# AT90PWM161 device description
Architecture: AVR8; Family: megaAVR
Registers are 8-bit, access not given, no defined reset value unless marked. A register's access mark holds for its fields unless they carry their own. Offsets are from the block's base; [hi:lo] are bit positions.

## FUSE — Fuses
Instances: FUSE 0 in fuses
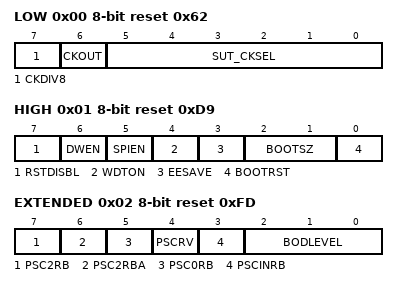
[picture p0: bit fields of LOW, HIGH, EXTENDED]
0x00 LOW reset 0x62
  [7] CKDIV8 — Divide clock by 8 internally
  [6] CKOUT — Clock output on PORTD1
  [5:0] SUT_CKSEL — Select Clock Source
    0=EXTCLK_PLLIN_RC_8MHZ_6CK_14CK_0MS (Ext. CK; PLLin: RC8; SUT: 6CK/14CK+0ms; [CKSEL=0000 SUT=00]); 16=EXTCLK_PLLIN_RC_8MHZ_6CK_14CK_4MS1 (Ext. CK; PLLin: RC8 MHz; SUT:6 CK/14CK+4.1 ms; [CKSEL=0000 SUT=01]); 32=EXTCLK_PLLIN_RC_8MHZ_6CK_14CK_65MS (Ext. CK; PLLin: RC8 MHz; SUT:6 CK/14CK+65 ms; [CKSEL=0000 SUT=10]); 2=RC_8MHZ_PLLIN_RC_8MHZ_6CK_14CK_0MS (RC8 MHz; PLLin: RC8; SUT: 6CK/14CK+0ms; [CKSEL=0010 SUT=00]); 18=RC_8MHZ_PLLIN_RC_8MHZ_6CK_14CK_4MS1 (RC8 MHz; PLLin: RC8; SUT: 6CK/14CK+4.1 ms; [CKSEL=0010 SUT=01]); 34=RC_8MHZ_PLLIN_RC_8MHZ_6CK_14CK_65MS (RC8 MHz; PLLin: RC8; SUT: 6CK/14CK+65 ms; [CKSEL=0010 SUT=10]); 8=XOSC_PLLIN_RC_8MHZ_258CK_14CK_4MS1 (XOSC.9-3MHz; PLLin: RC8; SUT: 258CK/14CK+4.1 ms; [CKSEL=1000 SUT=00]); 24=XOSC_PLLIN_RC_8MHZ_258CK_14CK_65MS (XOSC.9-3MHz; PLLin: RC8; SUT: 258CK/14CK+65 ms; [CKSEL=1000 SUT=01]); 40=XOSC_PLLIN_RC_8MHZ_1KCK_14CK_0MS (XOSC.9-3MHz; PLLin: RC8; SUT: 1KCK/14CK+0 ms; [CKSEL=1000 SUT=10]); 56=XOSC_PLLIN_RC_8MHZ_1KCK_14CK_4MS1 (XOSC.9-3MHz; PLLin: RC8; SUT: 1KCK/14CK+4.1 ms; [CKSEL=1000 SUT=11]); 9=XOSC_PLLIN_RC_8MHZ_1KCK_14CK_65MS (XOSC.9-3MHz; PLLin: RC8; SUT: 1KCK/14CK+65 ms; [CKSEL=1001 SUT=00]); 25=XOSC_PLLIN_RC_8MHZ_16KCK_14CK_0MS (XOSC.9-3MHz; PLLin: RC8; SUT: 16KCK/14CK+0 ms; [CKSEL=1001 SUT=01]); 41=XOSC_PLLIN_RC_8MHZ_16KCK_14CK_4MS1 (XOSC.9-3MHz; PLLin: RC8; SUT: 16KCK/14CK+4.1 ms; [CKSEL=1001 SUT=10]); 57=XOSC_PLLIN_RC_8MHZ_16KCK_14CK_65MS (XOSC.9-3MHz; PLLin: RC8; SUT: 16KCK/14CK+65 ms; [CKSEL=1001 SUT=11]); 10=XOSC_3MHZ_8MHZ_PLLIN_RC_8MHZ_258CK_14CK_4MS1 (XOSC3-8MHz; PLLin: RC8; SUT: 258CK/14CK+4.1 ms; [CKSEL=1010 SUT=00]); 26=XOSC_3MHZ_8MHZ_PLLIN_RC_8MHZ_258CK_14CK_65MS (XOSC3-8MHz; PLLin: RC8; SUT: 258CK/14CK+65 ms; [CKSEL=1010 SUT=01]); 42=XOSC_3MHZ_8MHZ_PLLIN_RC_8MHZ_1KCK_14CK_0MS (XOSC3-8MHz; PLLin: RC8; SUT: 1KCK/14CK+0 ms; [CKSEL=1010 SUT=10]); 58=XOSC_3MHZ_8MHZ_PLLIN_RC_8MHZ_1KCK_14CK_4MS1 (XOSC3-8MHz; PLLin: RC8; SUT: 1KCK/14CK+4.1 ms; [CKSEL=1010 SUT=11]); 11=XOSC_3MHZ_8MHZ_PLLIN_RC_8MHZ_1KCK_14CK_65MS (XOSC3-8MHz; PLLin: RC8; SUT: 1KCK/14CK+65 ms; [CKSEL=1011 SUT=00]); 27=XOSC_3MHZ_8MHZ_PLLIN_RC_8MHZ_16KCK_14CK_0MS (XOSC3-8MHz; PLLin: RC8; SUT: 16KCK/14CK+0 ms; [CKSEL=1011 SUT=01]); 43=XOSC_3MHZ_8MHZ_PLLIN_RC_8MHZ_16KCK_14CK_4MS1 (XOSC3-8MHz; PLLin: RC8; SUT: 16KCK/14CK+4.1 ms; [CKSEL=1011 SUT=10]); 59=XOSC_3MHZ_8MHZ_PLLIN_RC_8MHZ_16KCK_14CK_65MS (XOSC3-8MHz; PLLin: RC8; SUT: 16KCK/14CK+65 ms; [CKSEL=1011 SUT=11]); 12=XOSC_3MHZ_8MHZ_PLLIN_XOSC_258CK_14CK_4MS1 (XOSC3-8MHz; PLLin: XOSC; SUT: 258CK/14CK+4.1 ms; [CKSEL=1100 SUT=00]); 28=XOSC_3MHZ_8MHZ_PLLIN_XOSC_258CK_14CK_65MS (XOSC3-8MHz; PLLin: XOSC; SUT: 258CK/14CK+65 ms; [CKSEL=1100 SUT=01]); 44=XOSC_3MHZ_8MHZ_PLLIN_XOSC_1KCK_14CK_0MS (XOSC3-8MHz; PLLin: XOSC; SUT: 1KCK/14CK+0 ms; [CKSEL=1100 SUT=10]); 60=XOSC_3MHZ_8MHZ_PLLIN_XOSC_1KCK_14CK_4MS1 (XOSC3-8MHz; PLLin: XOSC; SUT: 1KCK/14CK+4.1 ms; [CKSEL=1100 SUT=11]); 13=XOSC_3MHZ_8MHZ_PLLIN_XOSC_1KCK_14CK_65MS (XOSC3-8MHz; PLLin: XOSC; SUT: 1KCK/14CK+65 ms; [CKSEL=1101 SUT=00); 29=XOSC_3MHZ_8MHZ_PLLIN_XOSC_16KCK_14CK_0MS (XOSC3-8MHz; PLLin: XOSC; SUT: 16KCK/14CK+0 ms; [CKSEL=1101 SUT=01]); 45=XOSC_3MHZ_8MHZ_PLLIN_XOSC_16KCK_14CK_4MS1 (XOSC3-8MHz; PLLin: XOSC; SUT: 16KCK/14CK+4.1 ms; [CKSEL=1101 SUT=10]); 61=XOSC_3MHZ_8MHZ_PLLIN_XOSC_16KCK_14CK_65MS (XOSC3-8MHz; PLLin: XOSC; SUT: 16KCK/14CK+65 ms; [CKSEL=1101 SUT=11]); 14=XOSC_8MHZ_16MHZ_PLLIN_RC_8MHZ_258CK_14CK_4MS1 (XOSC8-16MHz; PLLin: RC8; SUT: 258CK/14CK+4.1 ms; [CKSEL=1110 SUT=00]); 30=XOSC_8MHZ_16MHZ_PLLIN_RC_8MHZ_258CK_14CK_65MS (XOSC8-16MHz; PLLin: RC8; SUT: 258CK/14CK+65 ms; [CKSEL=1110 SUT=01]); 46=XOSC_8MHZ_16MHZ_PLLIN_RC_8MHZ_1KCK_14CK_0MS (XOSC8-16MHz; PLLin: RC8; SUT: 1KCK/14CK+0 ms; [CKSEL=1110 SUT=10]); 62=XOSC_8MHZ_16MHZ_PLLIN_RC_8MHZ_1KCK_14CK_4MS1 (XOSC8-16MHz; PLLin: RC8; SUT: 1KCK/14CK+4.1 ms; [CKSEL=1110 SUT=11]); 15=XOSC_8MHZ_16MHZ_PLLIN_RC_8MHZ_1KCK_14CK_65MS (XOSC8-16MHz; PLLin: RC8; SUT: 1KCK/14CK+65 ms; [CKSEL=1111 SUT=00]); 31=XOSC_8MHZ_16MHZ_PLLIN_RC_8MHZ_16KCK_14CK_0MS (XOSC8-16MHz; PLLin: RC8; SUT: 16KCK/14CK+0 ms; [CKSEL=1111 SUT=01]); 47=XOSC_8MHZ_16MHZ_PLLIN_RC_8MHZ_16KCK_14CK_4MS1 (XOSC8-16MHz; PLLin: RC8; SUT: 16KCK/14CK+4.1 ms; [CKSEL=1111 SUT=10]); 63=XOSC_8MHZ_16MHZ_PLLIN_RC_8MHZ_16KCK_14CK_65MS (XOSC8-16MHz; PLLin: RC8; SUT: 16KCK/14CK+65 ms; [CKSEL=1111 SUT=11]); 3=WDOSC_128KHZ_1KCK_14CK_0MS (WD128 KHz; SUT: 1KCK/14CK+0 ms; [CKSEL=0011 SUT=00]); 19=WDOSC_128KHZ_1KCK_14CK_4MS1 (WD128 KHz; SUT: 1KCK/14CK+4.1 ms; [CKSEL=0011 SUT=01]); 35=WDOSC_128KHZ_1KCK_14CK_65MS (WD128 KHz; SUT: 1KCK/14CK+65 ms; [CKSEL=0011 SUT=10]); 51=WDOSC_128KHZ_16KCK_14CK_0MS (WD128 KHz; SUT: 16KCK/14CK+0 ms; [CKSEL=0011 SUT=11]); 1=PLLCLK_DIV4_PLLIN_RC_8MHZ_1KCK_14CK_0MS (PLL/4; PLLin: RC8; SUT: 1KCK/14CK+0 ms; [CKSEL=0001 SUT=00]); 17=PLLCLK_DIV4_PLLIN_RC_8MHZ_1KCK_14CK_4MS (PLL/4; PLLin: RC8; SUT: 1KCK/14CK+4 ms; [CKSEL=0001 SUT=01]); 33=PLLCLK_DIV4_PLLIN_RC_8MHZ_1KCK_14CK_64MS (PLL/4; PLLin: RC8; SUT: 1KCK/14CK+64 ms; [CKSEL=0001 SUT=10]); 5=PLLCLK_DIV4_PLLIN_EXTCLK_16KCK_14CK_0MS (PLL/4; PLLin: Ext. CK; SUT: 16KCK/14CK+0 ms; [CKSEL=0101 SUT=00]); 21=PLLCLK_DIV4_PLLIN_EXTCLK_16KCK_14CK_4MS (PLL/4; PLLin: Ext. CK; SUT: 16KCK/14CK+4 ms; [CKSEL=0101 SUT=01]); 37=PLLCLK_DIV4_PLLIN_EXTCLK_16KCK_14CK_4MS (PLL/4; PLLin: Ext. CK; SUT: 16KCK/14CK+4 ms; [CKSEL=0101 SUT=10]); 53=PLLCLK_DIV4_PLLIN_EXTCLK_16KCK_14CK_64MS (PLL/4; PLLin: Ext. CK; SUT: 16KCK/14CK+64 ms; [CKSEL=0101 SUT=11]); 4=PLLCLK_DIV4_PLLIN_XOSC_1KCK_14CK_0MS (PLL/4; PLLin: XOSC; SUT: 1KCK/14CK+0 ms; [CKSEL=0100 SUT=00]); 20=PLLCLK_DIV4_PLLIN_XOSC_1KCK_14CK_4MS (PLL/4; PLLin: XOSC; SUT: 1KCK/14CK+4 ms; [CKSEL=0100 SUT=01]); 36=PLLCLK_DIV4_PLLIN_XOSC_1KCK_14CK_64MS (PLL/4; PLLin: XOSC; SUT: 1KCK/14CK+64 ms; [CKSEL=0100 SUT=10]); 52=PLLCLK_DIV4_PLLIN_XOSC_16KCK_14CK_0MS (PLL/4; PLLin: XOSC; SUT: 16KCK/14CK+0 ms; [CKSEL=0100 SUT=11]); 6=RC_1MHZ_1KCK_14CK_0MS (RC 1 MHz; SUT: 1KCK/14CK+0 ms; [CKSEL=0110 SUT=00]); 22=RC_1MHZ_1KCK_14CK_4MS1 (RC 1 MHz; SUT: 1KCK/14CK+4.1 ms; [CKSEL=0110 SUT=01]); 38=RC_1MHZ_1KCK_14CK_65MS (RC 1 MHz; SUT: 1KCK/14CK+65 ms; [CKSEL=0110 SUT=10])
0x01 HIGH reset 0xD9
  [7] RSTDISBL — Reset Disabled (Enable PE0 as I/O pin)
  [6] DWEN — Debug Wire enable
  [5] SPIEN — Serial program downloading (SPI) enabled
  [4] WDTON — Watch-dog Timer always on
  [3] EESAVE — Preserve EEPROM through the Chip Erase cycle
  [2:1] BOOTSZ — Select Boot Size
    3=128W_0F80 (Boot Flash size=128 words Boot address=$0F80); 2=256W_0F00 (Boot Flash size=256 words Boot address=$0F00); 1=512W_0E00 (Boot Flash size=512 words Boot address=$0E00); 0=1024W_0C00 (Boot Flash size=1024 words Boot address=$0C00)
  [0] BOOTRST — Select Reset Vector
0x02 EXTENDED reset 0xFD
  [7] PSC2RB — PSC2 Reset Behavior
  [6] PSC2RBA — PSC2 Reset Behavior for 22 and 23
  [5] PSC0RB — PSC0 Reset Behavior
  [4] PSCRV — PSC Reset Value
  [3] PSCINRB — PSC2 and PSC0 input Reset Behavior
  [2:0] BODLEVEL — Brown-out Detector Trigger Level
    7=DISABLED (Brown-out detection disabled); 6=1V8 (Brown-out detection at VCC=1.8 V); 5=2V7 (Brown-out detection at VCC=2.7 V); 4=4V3 (Brown-out detection at VCC=4.3 V); 3=2V3 (Brown-out detection at VCC=2.3 V); 2=2V2 (Brown-out detection at VCC=2.2 V); 1=1V9 (Brown-out detection at VCC=1.9 V); 0=2V0 (Brown-out detection at VCC=2.0 V)
